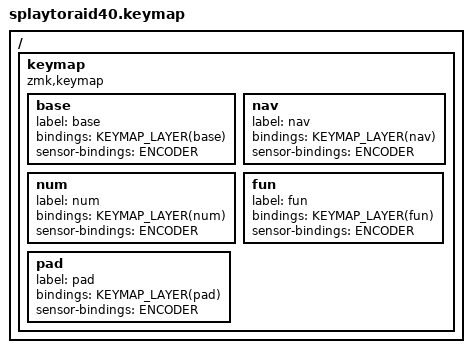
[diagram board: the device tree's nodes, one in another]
/*
 * Splaytoraid40 — thin keymap. Wired RP2040 unibody; vendored shield in
 * boards/shields/splaytoraid40/. Superset: outer pinky column on top+home rows,
 * 3 thumbs/hand + a center encoder-push. All key content lives in config/shared/;
 * the center encoder rotates volume down/up (sensor-bindings).
 */

#include <behaviors.dtsi>
#include <dt-bindings/zmk/keys.h>
#include <dt-bindings/zmk/bt.h>
#include <dt-bindings/zmk/outputs.h>

#include "geometry/geom_splaytoraid.h"

#include "shared/keys_de.h"
#include "shared/settings.dtsi"
#include "shared/behaviors.dtsi"
#include "shared/macros.dtsi"
#include "shared/combos.dtsi"
#include "shared/core_blocks.dtsi"

#define ENCODER  &inc_dec_kp C_VOL_DN C_VOL_UP

/ {
    keymap {
        compatible = "zmk,keymap";

        base { label = "base"; bindings = <KEYMAP_LAYER(base)>; sensor-bindings = <ENCODER>; };
        nav  { label = "nav";  bindings = <KEYMAP_LAYER(nav)>;  sensor-bindings = <ENCODER>; };
        num  { label = "num";  bindings = <KEYMAP_LAYER(num)>;  sensor-bindings = <ENCODER>; };
        fun  { label = "fun";  bindings = <KEYMAP_LAYER(fun)>;  sensor-bindings = <ENCODER>; };
        pad  { label = "pad";  bindings = <KEYMAP_LAYER(pad)>;  sensor-bindings = <ENCODER>; };
    };
};
